AUTOSAR XML (schema 4-2-1)
package /RootP_ASWC_M741
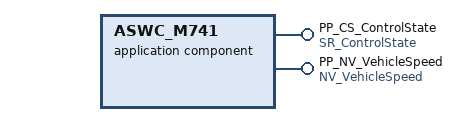
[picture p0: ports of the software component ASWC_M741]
  application sw component type ASWC_M741
    provide port PP_CS_ControlState: provided-interface=SR_ControlState
    provide port PP_NV_VehicleSpeed: provided-interface=NV_VehicleSpeed
package /RootP_Composition
  composition sw component type Compo_VSM
    component Instance_ASWC_M741: type=ASWC_M741
